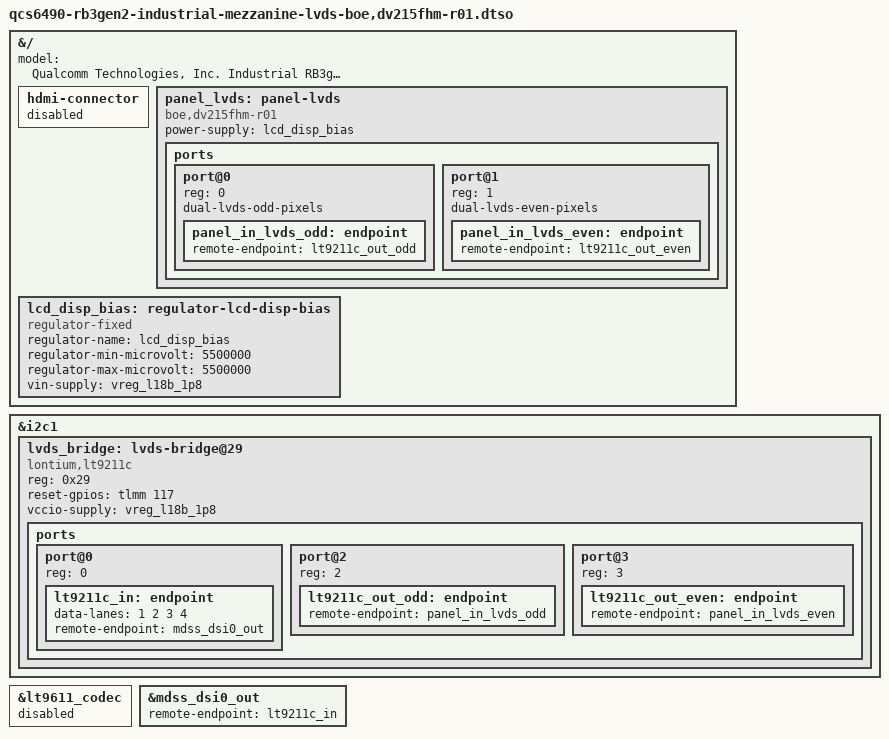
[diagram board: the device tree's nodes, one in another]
// SPDX-License-Identifier: BSD-3-Clause
/*
 * Copyright (c) Qualcomm Technologies, Inc. and/or its subsidiaries.
 */

/dts-v1/;
/plugin/;

#include <dt-bindings/gpio/gpio.h>

&{/} {
	model = "Qualcomm Technologies, Inc. Industrial RB3gen2 LVDS";

	hdmi-connector {
		status = "disabled";
	};

	panel_lvds: panel-lvds {
		compatible = "boe,dv215fhm-r01";
		power-supply = <&lcd_disp_bias>;

		ports {
			#address-cells = <1>;
			#size-cells = <0>;

			port@0 {
				reg = <0>;
				dual-lvds-odd-pixels;

				panel_in_lvds_odd: endpoint {
					remote-endpoint = <&lt9211c_out_odd>;
				};
			};

			port@1 {
				reg = <1>;
				dual-lvds-even-pixels;

				panel_in_lvds_even: endpoint {
					remote-endpoint = <&lt9211c_out_even>;
				};
			};
		};
	};

	lcd_disp_bias: regulator-lcd-disp-bias {
		compatible = "regulator-fixed";
		regulator-name = "lcd_disp_bias";
		regulator-min-microvolt = <5500000>;
		regulator-max-microvolt = <5500000>;
		vin-supply = <&vreg_l18b_1p8>;
        };
};

&i2c1 {
	#address-cells = <1>;
	#size-cells = <0>;

	status = "okay";

	lvds_bridge: lvds-bridge@29 {
		compatible = "lontium,lt9211c";
		reg = <0x29>;
		reset-gpios = <&tlmm 117 GPIO_ACTIVE_HIGH>;
		vccio-supply = <&vreg_l18b_1p8>;

		ports {
			#address-cells = <1>;
			#size-cells = <0>;

			port@0 {
				reg = <0>;

				lt9211c_in: endpoint {
					data-lanes = <1 2 3 4>;
					remote-endpoint = <&mdss_dsi0_out>;
				};
			};

			port@2 {
				reg = <2>;

				lt9211c_out_odd: endpoint {
					remote-endpoint = <&panel_in_lvds_odd>;
				};
			};

			port@3 {
				reg = <3>;

				lt9211c_out_even: endpoint {
					remote-endpoint = <&panel_in_lvds_even>;
				};
			};
		};
	};
};

&lt9611_codec {
	status = "disabled";
};

&mdss_dsi0_out {
	remote-endpoint = <&lt9211c_in>;
};

